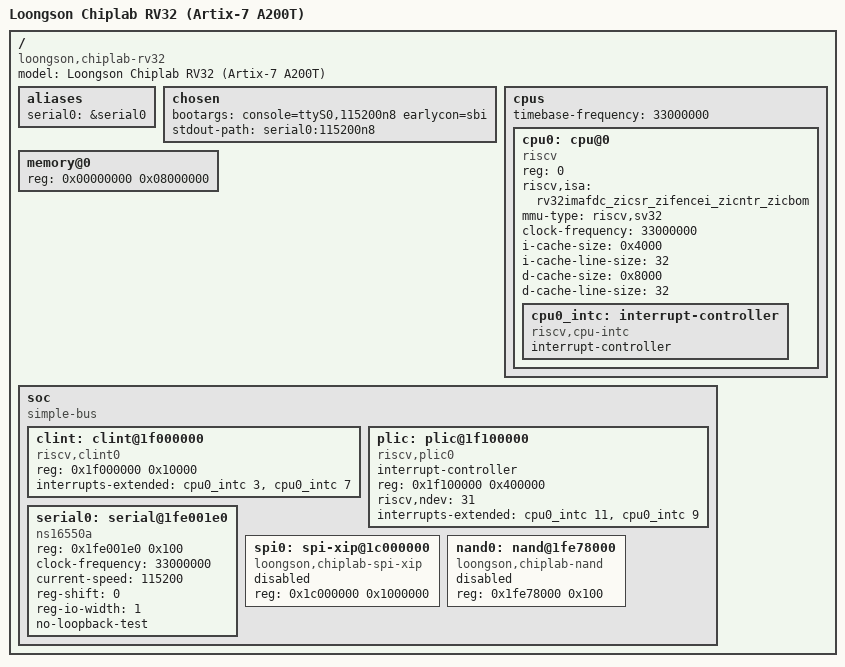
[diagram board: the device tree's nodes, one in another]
// SPDX-License-Identifier: GPL-2.0+
/*
 * Loongson Chiplab RV32 board (chiplab FPGA SoC on Xilinx Artix-7 A200T)
 *
 * 地址口径唯一真源：rv32gc-cpu/docs/kb/platform-facts.md
 *   DDR3        0x0000_0000 - 0x07FF_FFFF (128 MiB)   §2.1
 *   SPI XIP     0x1C00_0000 (别名 0x1FE8_0000, 16 MiB) §2.3
 *   UART 16550  0x1FE0_01E0 (33 MHz, 115200)           §2.5 / §5
 *   NAND        0x1FE7_8000 (预留, 见 docs/porting/04-nand-driver.md)
 *   CLINT       0x1F00_0000 (核内私有, 平台 AXI 不译码) §2.4
 *   PLIC        0x1F10_0000 (同上)                      §2.4
 *
 * U-Boot 运行在 S 模式：定时器/IPI/复位走 SBI，本树只描述地址与串口。
 */

/dts-v1/;

/ {
	#address-cells = <1>;
	#size-cells = <1>;
	compatible = "loongson,chiplab-rv32";
	model = "Loongson Chiplab RV32 (Artix-7 A200T)";

	aliases {
		serial0 = &serial0;
	};

	chosen {
		bootargs = "console=ttyS0,115200n8 earlycon=sbi";
		stdout-path = "serial0:115200n8";
	};

	cpus {
		#address-cells = <1>;
		#size-cells = <0>;
		/* 33 MHz uncore 域，platform-facts.md §5（config.h:33 FREQ） */
		timebase-frequency = <33000000>;

		cpu0: cpu@0 {
			device_type = "cpu";
			reg = <0>;
			status = "okay";
			compatible = "riscv";
			riscv,isa = "rv32imafdc_zicsr_zifencei_zicntr_zicbom";
			mmu-type = "riscv,sv32";
			clock-frequency = <33000000>;
			i-cache-size = <0x4000>;	/* L1I 16 KiB */
			i-cache-line-size = <32>;
			d-cache-size = <0x8000>;	/* L1D 32 KiB */
			d-cache-line-size = <32>;

			cpu0_intc: interrupt-controller {
				#interrupt-cells = <1>;
				interrupt-controller;
				compatible = "riscv,cpu-intc";
			};
		};
	};

	memory@0 {
		device_type = "memory";
		/* DDR3 128 MiB，platform-facts.md §2.1 */
		reg = <0x00000000 0x08000000>;
	};

	soc {
		#address-cells = <1>;
		#size-cells = <1>;
		compatible = "simple-bus";
		ranges;

		/*
		 * CLINT / PLIC 由核内译码（平台 AXI 不译码这两个窗口，
		 * 见 platform-facts.md §2.4 与 §9 U8）。U-Boot(S) 不直接使用它们；
		 * 节点为 OpenSBI / Linux 保留。
		 */
		clint: clint@1f000000 {
			compatible = "riscv,clint0";
			reg = <0x1f000000 0x10000>;
			interrupts-extended = <&cpu0_intc 3 &cpu0_intc 7>;
		};

		plic: plic@1f100000 {
			compatible = "riscv,plic0";
			#interrupt-cells = <2>;
			interrupt-controller;
			reg = <0x1f100000 0x400000>;
			riscv,ndev = <31>;
			interrupts-extended = <&cpu0_intc 11 &cpu0_intc 9>;
		};

		/*
		 * 16550 UART：寄存器按字节排列（reg-shift=0 / reg-io-width=1）。
		 * 依据：平台 UART_TOP.PADDR[2:0] 直接作寄存器号（URT/uart_top.v:86），
		 * axi2apb_bridge 把 AXI 字节地址原样送到 APB（axi2apb.v:168,216）；
		 * 旧树 la32r-uboot 同 IP 用 CONFIG_DEBUG_UART_SHIFT=0。
		 * 33 MHz / 115200：旧树 la32rsoc_defconfig 的 DEBUG_UART_CLOCK 口径，
		 * 平台事实 §5（FREQ=33 MHz）。
		 */
		serial0: serial@1fe001e0 {
			compatible = "ns16550a";
			reg = <0x1fe001e0 0x100>;
			clock-frequency = <33000000>;
			current-speed = <115200>;
			reg-shift = <0>;
			reg-io-width = <1>;
			no-loopback-test;
		};

		/*
		 * SPI XIP 窗口（引导 ROM 介质）。U-Boot 在 S 模式由 OpenSBI 装载到
		 * DDR3 运行，不使用 XIP；此节点只登记地址口径，等待 SPI 驱动阶段。
		 */
		spi0: spi-xip@1c000000 {
			compatible = "loongson,chiplab-spi-xip";
			reg = <0x1c000000 0x1000000>;
			status = "disabled";
		};

		/*
		 * APB NAND 控制器（K9F1G08U0C，128 MiB）：本阶段只预留地址，
		 * 驱动与分区见 rv32gc-cpu/docs/porting/04-nand-driver.md。
		 */
		nand0: nand@1fe78000 {
			compatible = "loongson,chiplab-nand";
			reg = <0x1fe78000 0x100>;
			status = "disabled";
		};
	};
};
